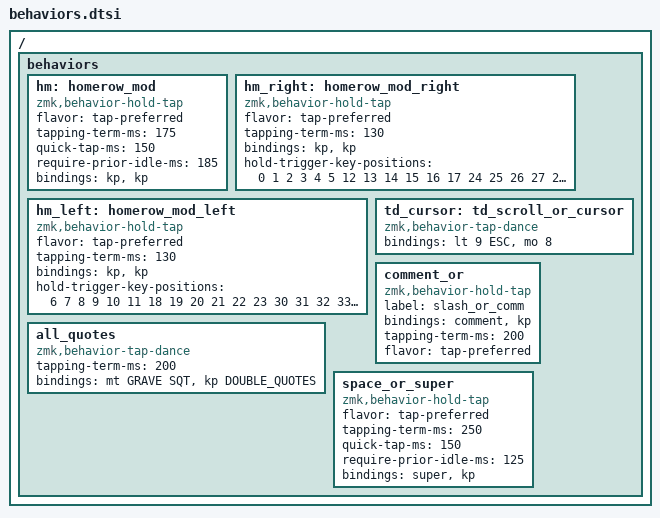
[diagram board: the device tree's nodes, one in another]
/ {
    behaviors {
        hm: homerow_mod {
            compatible = "zmk,behavior-hold-tap";
            #binding-cells = <2>;
            flavor = "tap-preferred";
            tapping-term-ms = <175>; // triggers the hold behavior when the tapping-term-ms has expired
            quick-tap-ms = <150>; // If you press a tapped hold-tap again within quick-tap-ms milliseconds of the first press, it will always trigger the tap behavior.
            require-prior-idle-ms = <185>; // like quick-tap-ms however it will apply for any non-modifier key pressed before it
            bindings = <&kp>, <&kp>;  // hold, tap
        };

        hm_right: homerow_mod_right {
            compatible = "zmk,behavior-hold-tap";
            #binding-cells = <2>;
            flavor = "tap-preferred";
            tapping-term-ms = <130>;
            // quick-tap-ms = <200>;
            // require-prior-idle-ms = <150>;
            bindings = <&kp>, <&kp>;
            hold-trigger-key-positions = <0 1 2 3 4 5 12 13 14 15 16 17 24 25 26 27 28 29 36 37 38>;
        };

        hm_left: homerow_mod_left {
            compatible = "zmk,behavior-hold-tap";
            #binding-cells = <2>;
            flavor = "tap-preferred";
            tapping-term-ms = <130>;
            // quick-tap-ms = <200>;
            // require-prior-idle-ms = <150>;
            bindings = <&kp>, <&kp>;
            hold-trigger-key-positions = <6 7 8 9 10 11 18 19 20 21 22 23 30 31 32 33 34 35 39 40>;
        };

        td_cursor: td_scroll_or_cursor {
            compatible = "zmk,behavior-tap-dance";
            #binding-cells = <0>;
            bindings = <&lt 9 ESC>, <&mo 8>; // hold, tap, double_tap
        };

        comment_or: comment_or {
            compatible = "zmk,behavior-hold-tap";
            label = "slash_or_comm";
            bindings = <&comment>, <&kp>;

            #binding-cells = <2>;
            tapping-term-ms = <200>;
            flavor = "tap-preferred";
        };

        all_quotes: all_quotes {
            compatible = "zmk,behavior-tap-dance";
            #binding-cells = <0>;
            tapping-term-ms = <200>;
            bindings = <&mt GRAVE SQT>, <&kp DOUBLE_QUOTES>;
        };

        space_or_super: space_or_super {
            compatible = "zmk,behavior-hold-tap";
            #binding-cells = <2>;
            flavor = "tap-preferred";
            tapping-term-ms = <250>;
            quick-tap-ms = <150>;
            require-prior-idle-ms = <125>;
            bindings = <&super>, <&kp>;
        };

    };
};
